AUTOSAR XML (schema 4-3-0)
standard types defined: UINT8, UINT16, UINT32, UINT64, SINT8, SINT16, SINT32, FLOAT32, FLOAT64
package /Pkg_ErrorMgrSat_2_0_QM/ComponentTypes
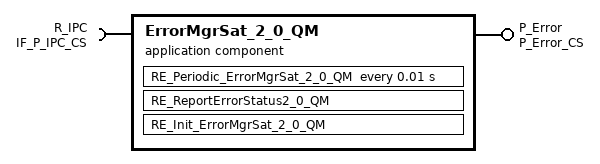
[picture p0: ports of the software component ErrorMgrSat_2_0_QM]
  application sw component type ErrorMgrSat_2_0_QM
    provide port P_Error: server-com-spec{operation=ReportErrorStatus2_0_QM, queue-length=1}, provided-interface=P_Error_CS
    require port R_IPC: client-com-spec=IPC_Write_v, required-interface=IF_P_IPC_CS
    behavior ErrorMgrSat_2_0_QM_InternalBehavior: handle-termination-and-restart=NO-SUPPORT
      timing event TMT_RE_Periodic_ErrorMgrSat_2_0_QM: start-on-event=RE_Periodic_ErrorMgrSat_2_0_QM, period=0.01
      operation invoked event OIT_RE_ReportErrorStatus2_0_QM_P_Error_ReportErrorStatus2_0_QM: start-on-event=RE_ReportErrorStatus2_0_QM, operation=P_Error.ReportErrorStatus2_0_QM
      init event InitEvent: start-on-event=RE_Init_ErrorMgrSat_2_0_QM
      port-api-options:
        enable-take-address=false, indirect-api=false, port=P_Error
        enable-take-address=false, indirect-api=false, port=R_IPC
      runnable RE_Periodic_ErrorMgrSat_2_0_QM  # Periodic Runnable of Satellite
        sync call SC_R_IPC_IPC_Write_v: operation=R_IPC.IPC_Write_v, timeout=0
      runnable RE_ReportErrorStatus2_0_QM: can-be-invoked-concurrently=true  # Server Runnable for handling the error reporting
      runnable RE_Init_ErrorMgrSat_2_0_QM  # Init Runnable
  swc implementation ErrorMgrSat_2_0_QM_Implementation: programming-language=C, vendor-id=0, behavior=ErrorMgrSat_2_0_QM_InternalBehavior
    code-descriptors:
      code Default: artifact-descriptors=autosar-engineering-object={short-label=Default, category=SWSRC}
package /Pkg_ErrorMgrSat_2_0_QM/ImplementationDataTypes
  30 x impl type, all with type-emitter=RTE:
    BOOL: implementation-data-type=boolean
    ErrorMgr_ErrorField: implementation-data-type=uint8
    Error1_0QM_arr: category=ARRAY
      element Elem_ErrorMgr_ErrorField: array-size=12, array-size-semantics=FIXED-SIZE, implementation-data-type=ErrorMgr_ErrorField
    Data1_0QM_arr: category=ARRAY
      element Elem_ErrorMgr_stAddData: array-size=12, array-size-semantics=FIXED-SIZE, implementation-data-type=ErrorMgr_stAddData
    Error1_0B_arr: category=ARRAY
      element Elem_ErrorMgr_ErrorField: array-size=400, array-size-semantics=FIXED-SIZE, implementation-data-type=ErrorMgr_ErrorField
    Data1_0B_arr: category=ARRAY
      element Elem_ErrorMgr_stAddData: array-size=400, array-size-semantics=FIXED-SIZE, implementation-data-type=ErrorMgr_stAddData
    Error2_0QM_arr: category=ARRAY
      element Elem_ErrorMgr_ErrorField: array-size=1, array-size-semantics=FIXED-SIZE, implementation-data-type=ErrorMgr_ErrorField
    Padding2_0QM_arr: category=ARRAY
      element Elem_ErrorMgr_ErrorField: array-size=3, array-size-semantics=FIXED-SIZE, implementation-data-type=ErrorMgr_ErrorField
    Data2_0QM_arr: category=ARRAY
      element Elem_ErrorMgr_stAddData: array-size=1, array-size-semantics=FIXED-SIZE, implementation-data-type=ErrorMgr_stAddData
    Error2_0B_arr: category=ARRAY
      element Elem_ErrorMgr_ErrorField: array-size=144, array-size-semantics=FIXED-SIZE, implementation-data-type=ErrorMgr_ErrorField
    Data2_0B_arr: category=ARRAY
      element Elem_ErrorMgr_stAddData: array-size=144, array-size-semantics=FIXED-SIZE, implementation-data-type=ErrorMgr_stAddData
    Error2_1QM_arr: category=ARRAY
      element Elem_ErrorMgr_ErrorField: array-size=1, array-size-semantics=FIXED-SIZE, implementation-data-type=ErrorMgr_ErrorField
    Padding2_1QM_arr: category=ARRAY
      element Elem_ErrorMgr_ErrorField: array-size=3, array-size-semantics=FIXED-SIZE, implementation-data-type=ErrorMgr_ErrorField
    Data2_1QM_arr: category=ARRAY
      element Elem_ErrorMgr_stAddData: array-size=1, array-size-semantics=FIXED-SIZE, implementation-data-type=ErrorMgr_stAddData
    Error2_1B_arr: category=ARRAY
      element Elem_ErrorMgr_ErrorField: array-size=548, array-size-semantics=FIXED-SIZE, implementation-data-type=ErrorMgr_ErrorField
    Data2_1B_arr: category=ARRAY
      element Elem_ErrorMgr_stAddData: array-size=548, array-size-semantics=FIXED-SIZE, implementation-data-type=ErrorMgr_stAddData
    ErrorQNXQM_arr: category=ARRAY
      element Elem_ErrorMgr_ErrorField: array-size=1, array-size-semantics=FIXED-SIZE, implementation-data-type=ErrorMgr_ErrorField
    PaddingQNXQM_arr: category=ARRAY
      element Elem_ErrorMgr_ErrorField: array-size=3, array-size-semantics=FIXED-SIZE, implementation-data-type=ErrorMgr_ErrorField
    DataQNXQM_arr: category=ARRAY
      element Elem_ErrorMgr_stAddData: array-size=1, array-size-semantics=FIXED-SIZE, implementation-data-type=ErrorMgr_stAddData
    ErrorQNXB_arr: category=ARRAY
      element Elem_ErrorMgr_ErrorField: array-size=8, array-size-semantics=FIXED-SIZE, implementation-data-type=ErrorMgr_ErrorField
    DataQNXB_arr: category=ARRAY
      element Elem_ErrorMgr_stAddData: array-size=8, array-size-semantics=FIXED-SIZE, implementation-data-type=ErrorMgr_stAddData
    AdditionalData_arr: category=ARRAY
      element Elem_uint8: array-size=4, array-size-semantics=FIXED-SIZE, implementation-data-type=uint8
    ErrorMgr_enErrorNo: compu {0=ErrorMgr_Error_MissingMessage_ORC_FD1, 1=ErrorMgr_Error_DLC_Fault_ORC_FD1, 2=ErrorMgr_Error_MissingMessage_TRSKM_FD_1, 3=ErrorMgr_Error_DLC_Fault_TRSKM_FD_1, 4=ErrorMgr_Error_TRSC_EnableBtn_Sts_Invld, 5=ErrorMgr_Error_TRSC_CenterBtn_Sts_Invld, 6=ErrorMgr_Error_CRC_Fault_TRSKM, 7=ErrorMgr_Error_MC_Fault_TRSKM, 8=ErrorMgr_Error_SBR1RowDriverSeatSts_Invld, 9=ErrorMgr_Error_CRC_Fault_ORC, 10=ErrorMgr_Error_MC_Fault_ORC, 11=ErrorMgr_Error_TRSC_RawKnob_OOR_Fault, 1112=ErrorMgr_ErrorNum_Max}, implementation-data-type=uint32
    ErrorMgr_enSafeStates: compu {0=ErrorMgr_SafeState_safestate1, 1=ErrorMgr_SafeState_safestate16, 2=ErrorMgr_SafeState_safestate23, 3=ErrorMgr_SafeState_safestate24, 4=ErrorMgr_SafeState_safestate17, 5=ErrorMgr_SafeState_safestate13, 6=ErrorMgr_SafeState_safestate12, 7=ErrorMgr_SafeState_safestate9, 8=ErrorMgr_SafeState_safestate10, 9=ErrorMgr_SafeState_safestate7, 10=ErrorMgr_SafeState_safestate4, 11=ErrorMgr_SafeState_safestate2, 12=ErrorMgr_SafeState_safestate5, 13=ErrorMgr_SafeState_safestate11, 14=ErrorMgr_SafeState_safestate21, 15=ErrorMgr_SafeState_Max}, implementation-data-type=uint32
    ErrorMgr_enErrorStatus: compu {0=ErrorMgr_Invalid, 1=ErrorMgr_ErrorInactive, 2=ErrorMgr_ErrorActive}, implementation-data-type=uint32
    ErrorMgr_ErrorCommPack_1_0_QM: category=STRUCTURE
      4 x element, all with category=TYPE_REFERENCE:
        RunningCounter: implementation-data-type=uint32
        Checksum: implementation-data-type=uint32
        Error: implementation-data-type=Error1_0QM_arr
        Data: implementation-data-type=Data1_0QM_arr
    ErrorMgr_ErrorCommPack_2_0_QM: category=STRUCTURE
      5 x element, all with category=TYPE_REFERENCE:
        RunningCounter: implementation-data-type=uint32
        Checksum: implementation-data-type=uint32
        Error: implementation-data-type=Error2_0QM_arr
        Padding: implementation-data-type=Padding2_0QM_arr
        Data: implementation-data-type=Data2_0QM_arr
    ErrorMgr_ErrorCommPack_2_1_QM: category=STRUCTURE
      5 x element, all with category=TYPE_REFERENCE:
        RunningCounter: implementation-data-type=uint32
        Checksum: implementation-data-type=uint32
        Error: implementation-data-type=Error2_1QM_arr
        Padding: implementation-data-type=Padding2_1QM_arr
        Data: implementation-data-type=Data2_1QM_arr
    ErrorMgr_ErrorCommPack_QNX_QM: category=STRUCTURE
      5 x element, all with category=TYPE_REFERENCE:
        RunningCounter: implementation-data-type=uint32
        Checksum: implementation-data-type=uint32
        Error: implementation-data-type=ErrorQNXQM_arr
        Padding: implementation-data-type=PaddingQNXQM_arr
        Data: implementation-data-type=DataQNXQM_arr
    ErrorMgr_stAddData: category=STRUCTURE
      element AdditionalData: implementation-data-type=AdditionalData_arr
package /Pkg_ErrorMgrSat_2_0_QM/PortInterfaces
  client server interface P_Error_CS
    operation ReportErrorStatus2_0_QM: possible-error=E_NOK
      arg err: type=ErrorMgr_enErrorNo, direction=IN, server-argument-impl-policy=USE-ARGUMENT-TYPE
      arg errStatus: type=ErrorMgr_enErrorStatus, direction=IN, server-argument-impl-policy=USE-ARGUMENT-TYPE
      arg addData: type=ErrorMgr_stAddData, direction=IN, server-argument-impl-policy=USE-ARGUMENT-TYPE
    error E_NOK: error-code=1
